# iostm32f205zx register map
Registers are 32-bit, access not given, no defined reset value unless marked. A register's access mark holds for its fields unless they carry their own. Addresses are absolute; registers are grouped by the start of their names; [hi:lo] are bit positions; {n}, {i} and the like mark numbered series; 'fields as' and 'values as' point back to an identical list.

## RTC
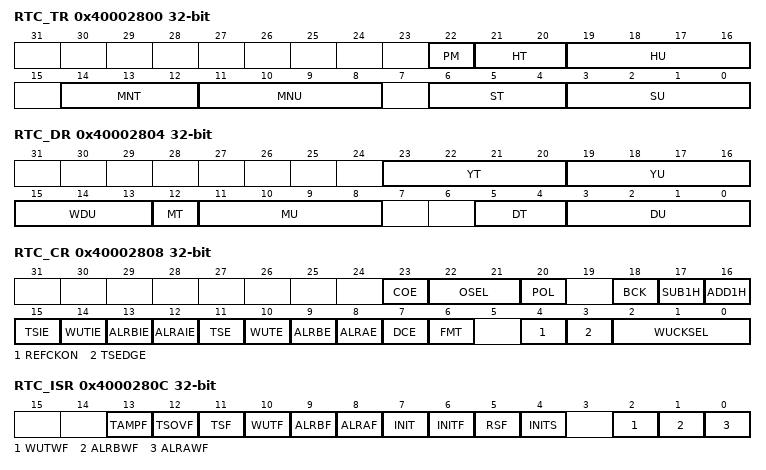
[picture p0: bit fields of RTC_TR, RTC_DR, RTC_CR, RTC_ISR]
0x40002800 RTC_TR
  [22] PM, [21:20] HT, [19:16] HU, [14:12] MNT, [11:8] MNU, [6:4] ST, [3:0] SU
0x40002804 RTC_DR
  [23:20] YT, [19:16] YU, [15:13] WDU, [12] MT, [11:8] MU, [5:4] DT, [3:0] DU
0x40002808 RTC_CR
  [23] COE, [22:21] OSEL, [20] POL, [18] BCK, [17] SUB1H, [16] ADD1H, [15] TSIE, [14] WUTIE, [13] ALRBIE, [12] ALRAIE, [11] TSE, [10] WUTE, [9] ALRBE, [8] ALRAE, [7] DCE, [6] FMT, [4] REFCKON, [3] TSEDGE, [2:0] WUCKSEL
0x4000280C RTC_ISR
  [13] TAMPF, [12] TSOVF, [11] TSF, [10] WUTF, [9] ALRBF, [8] ALRAF, [7] INIT, [6] INITF, [5] RSF, [4] INITS, [2] WUTWF, [1] ALRBWF, [0] ALRAWF
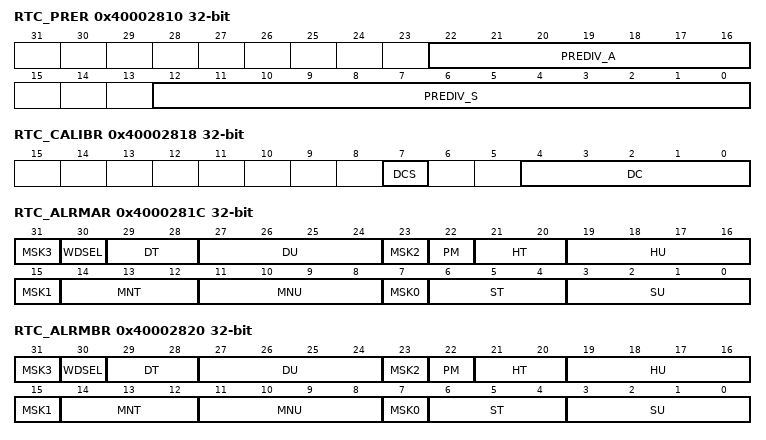
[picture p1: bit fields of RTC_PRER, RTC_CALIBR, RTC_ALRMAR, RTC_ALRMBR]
0x40002810 RTC_PRER
  [22:16] PREDIV_A, [12:0] PREDIV_S
0x40002814 RTC_WUTR
  [15:0] WUARV
0x40002818 RTC_CALIBR
  [7] DCS, [4:0] DC
0x4000281C RTC_ALRMAR
  [8n+7] MSK{n} (n=0..3), [30] WDSEL, [29:28] DT, [27:24] DU, [22] PM, [21:20] HT, [19:16] HU, [14:12] MNT, [11:8] MNU, [6:4] ST, [3:0] SU
0x40002820 RTC_ALRMBR
  fields as RTC_ALRMAR
0x40002824 RTC_WPR
  [7:0] KEY
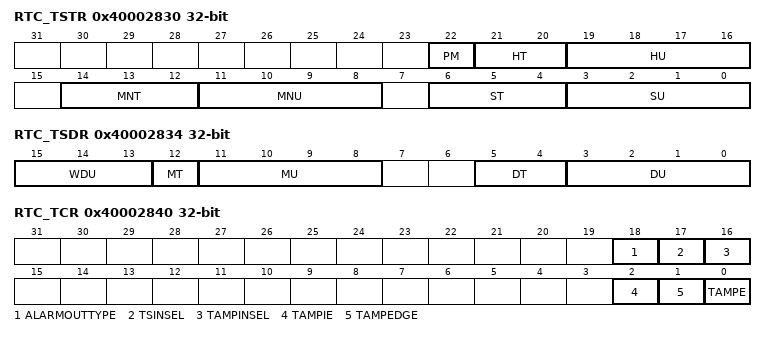
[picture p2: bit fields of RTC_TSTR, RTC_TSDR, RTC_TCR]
0x40002830 RTC_TSTR
  fields as RTC_TR
0x40002834 RTC_TSDR
  [15:13] WDU, [12] MT, [11:8] MU, [5:4] DT, [3:0] DU
0x40002840 RTC_TCR
  [18] ALARMOUTTYPE, [17] TSINSEL, [16] TAMPINSEL, [2] TAMPIE, [1] TAMPEDGE, [0] TAMPE
{0x40002850+4i} RTC_BK{i}R (i=0..19)

## IWDG
0x40003000 IWDG_KR 16-bit
0x40003004 IWDG_PR 16-bit
  [2:0] PR
0x40003008 IWDG_RLR 16-bit
  [11:0] RL
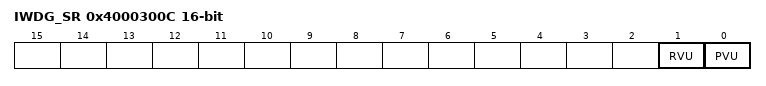
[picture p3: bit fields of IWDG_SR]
0x4000300C IWDG_SR 16-bit
  [1] RVU, [0] PVU

## WWDG
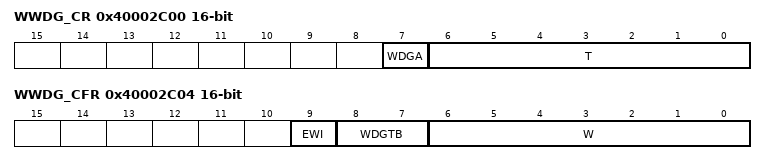
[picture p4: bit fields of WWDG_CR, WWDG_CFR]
0x40002C00 WWDG_CR 16-bit
  [7] WDGA, [6:0] T
0x40002C04 WWDG_CFR 16-bit
  [9] EWI, [8:7] WDGTB, [6:0] W
0x40002C08 WWDG_SR 16-bit
  [0] EWIF

## RNG
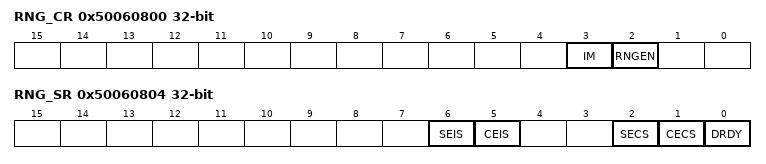
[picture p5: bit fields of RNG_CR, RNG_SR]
0x50060800 RNG_CR
  [3] IM, [2] RNGEN
0x50060804 RNG_SR
  [6] SEIS, [5] CEIS, [2] SECS, [1] CECS, [0] DRDY
0x50060808 RNG_DR

## TIM1
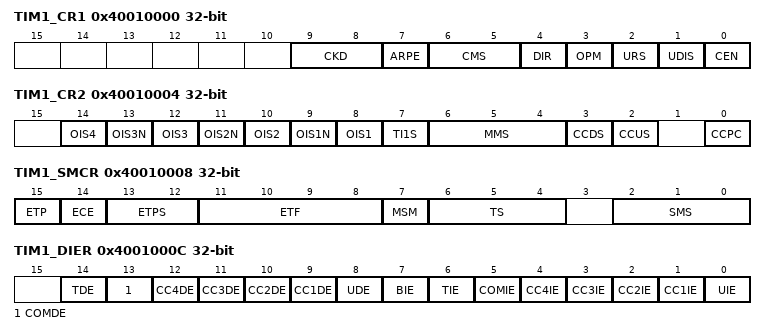
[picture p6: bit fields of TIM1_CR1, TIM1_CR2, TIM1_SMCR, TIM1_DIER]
0x40010000 TIM1_CR1
  [9:8] CKD, [7] ARPE, [6:5] CMS, [4] DIR, [3] OPM, [2] URS, [1] UDIS, [0] CEN
0x40010004 TIM1_CR2
  [2n+6] OIS{n} (n=1..4), [13] OIS3N, [11] OIS2N, [9] OIS1N, [7] TI1S, [6:4] MMS, [3] CCDS, [2] CCUS, [0] CCPC
0x40010008 TIM1_SMCR
  [15] ETP, [14] ECE, [13:12] ETPS, [11:8] ETF, [7] MSM, [6:4] TS, [2:0] SMS
0x4001000C TIM1_DIER
  [14] TDE, [13] COMDE, [n+8] CC{n}DE (n=1..4), [8] UDE, [7] BIE, [6] TIE, [5] COMIE, [n] CC{n}IE (n=1..4), [0] UIE
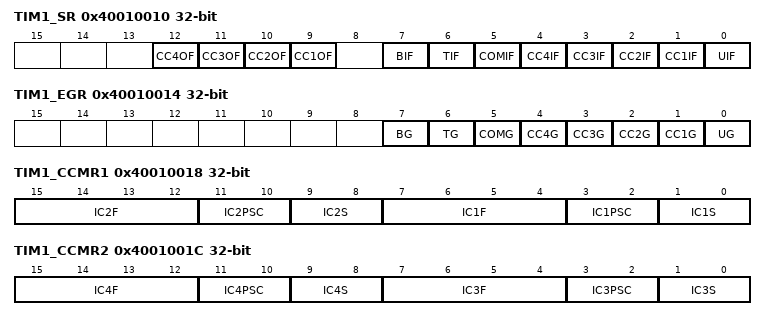
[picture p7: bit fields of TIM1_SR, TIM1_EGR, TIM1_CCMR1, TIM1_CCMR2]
0x40010010 TIM1_SR
  [n+8] CC{n}OF (n=1..4), [7] BIF, [6] TIF, [5] COMIF, [n] CC{n}IF (n=1..4), [0] UIF
0x40010014 TIM1_EGR
  [7] BG, [6] TG, [5] COMG, [n] CC{n}G (n=1..4), [0] UG
0x40010018 TIM1_CCMR1
  [15:12] IC2F, [11:10] IC2PSC, [9:8] IC2S, [7:4] IC1F, [3:2] IC1PSC, [1:0] IC1S
0x40010018 TIM1_OCMR1
0x4001001C TIM1_CCMR2
  [15:12] IC4F, [11:10] IC4PSC, [9:8] IC4S, [7:4] IC3F, [3:2] IC3PSC, [1:0] IC3S
0x4001001C TIM1_OCMR2
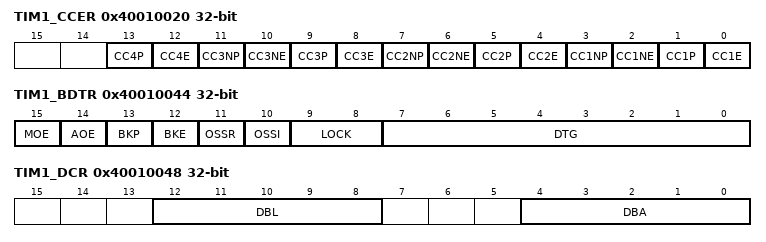
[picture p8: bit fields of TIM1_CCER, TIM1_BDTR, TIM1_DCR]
0x40010020 TIM1_CCER
  [4n-3] CC{n}P (n=1..4), [4n-4] CC{n}E (n=1..4), [11] CC3NP, [10] CC3NE, [7] CC2NP, [6] CC2NE, [3] CC1NP, [2] CC1NE
0x40010024 TIM1_CNT
  [15:0] CNT
0x40010028 TIM1_PSC
  [15:0] PSC
0x4001002C TIM1_ARR
  [15:0] ARR
0x40010030 TIM1_RCR
  [7:0] REP
{0x40010030+4i} TIM1_CCR{i} (i=1..4)
  [15:0] CCR
0x40010044 TIM1_BDTR
  [15] MOE, [14] AOE, [13] BKP, [12] BKE, [11] OSSR, [10] OSSI, [9:8] LOCK, [7:0] DTG
0x40010048 TIM1_DCR
  [12:8] DBL, [4:0] DBA
0x4001004C TIM1_DMAR
  [15:0] DMAB
0x40010418 TIM1_OCMR8

## TIM8
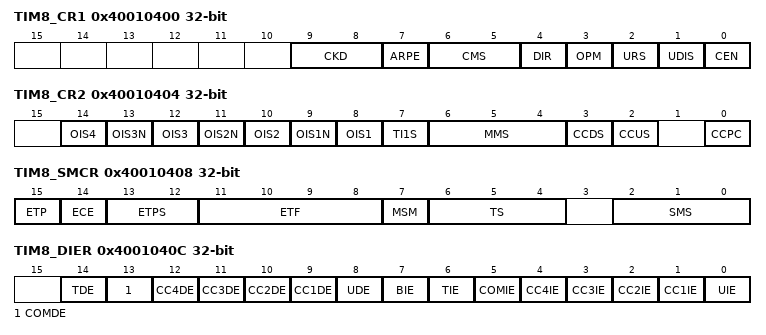
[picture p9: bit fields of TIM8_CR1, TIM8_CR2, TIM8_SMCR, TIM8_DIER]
0x40010400 TIM8_CR1
  [9:8] CKD, [7] ARPE, [6:5] CMS, [4] DIR, [3] OPM, [2] URS, [1] UDIS, [0] CEN
0x40010404 TIM8_CR2
  [2n+6] OIS{n} (n=1..4), [13] OIS3N, [11] OIS2N, [9] OIS1N, [7] TI1S, [6:4] MMS, [3] CCDS, [2] CCUS, [0] CCPC
0x40010408 TIM8_SMCR
  [15] ETP, [14] ECE, [13:12] ETPS, [11:8] ETF, [7] MSM, [6:4] TS, [2:0] SMS
0x4001040C TIM8_DIER
  [14] TDE, [13] COMDE, [n+8] CC{n}DE (n=1..4), [8] UDE, [7] BIE, [6] TIE, [5] COMIE, [n] CC{n}IE (n=1..4), [0] UIE
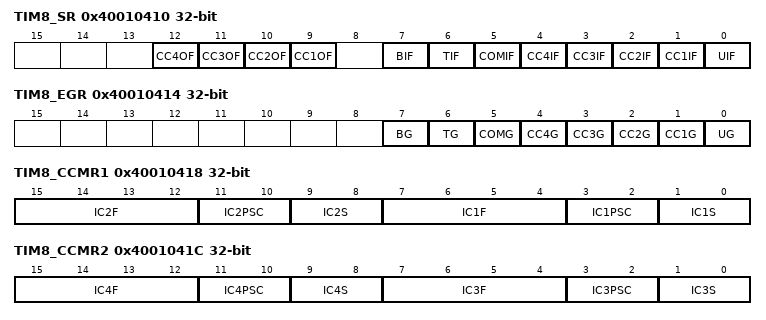
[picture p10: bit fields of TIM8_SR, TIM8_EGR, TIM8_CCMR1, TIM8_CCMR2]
0x40010410 TIM8_SR
  [n+8] CC{n}OF (n=1..4), [7] BIF, [6] TIF, [5] COMIF, [n] CC{n}IF (n=1..4), [0] UIF
0x40010414 TIM8_EGR
  [7] BG, [6] TG, [5] COMG, [n] CC{n}G (n=1..4), [0] UG
0x40010418 TIM8_CCMR1
  [15:12] IC2F, [11:10] IC2PSC, [9:8] IC2S, [7:4] IC1F, [3:2] IC1PSC, [1:0] IC1S
0x4001041C TIM8_CCMR2
  [15:12] IC4F, [11:10] IC4PSC, [9:8] IC4S, [7:4] IC3F, [3:2] IC3PSC, [1:0] IC3S
0x4001041C TIM8_OCMR2
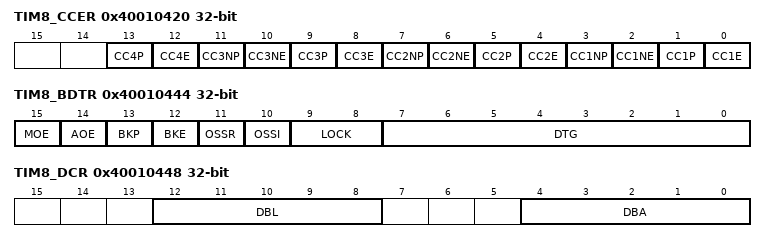
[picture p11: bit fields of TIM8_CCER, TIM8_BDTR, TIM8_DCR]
0x40010420 TIM8_CCER
  [4n-3] CC{n}P (n=1..4), [4n-4] CC{n}E (n=1..4), [11] CC3NP, [10] CC3NE, [7] CC2NP, [6] CC2NE, [3] CC1NP, [2] CC1NE
0x40010424 TIM8_CNT
  [15:0] CNT
0x40010428 TIM8_PSC
  [15:0] PSC
0x4001042C TIM8_ARR
  [15:0] ARR
0x40010430 TIM8_RCR
  [7:0] REP
{0x40010430+4i} TIM8_CCR{i} (i=1..4)
  [15:0] CCR
0x40010444 TIM8_BDTR
  [15] MOE, [14] AOE, [13] BKP, [12] BKE, [11] OSSR, [10] OSSI, [9:8] LOCK, [7:0] DTG
0x40010448 TIM8_DCR
  [12:8] DBL, [4:0] DBA
0x4001044C TIM8_DMAR
  [15:0] DMAB
